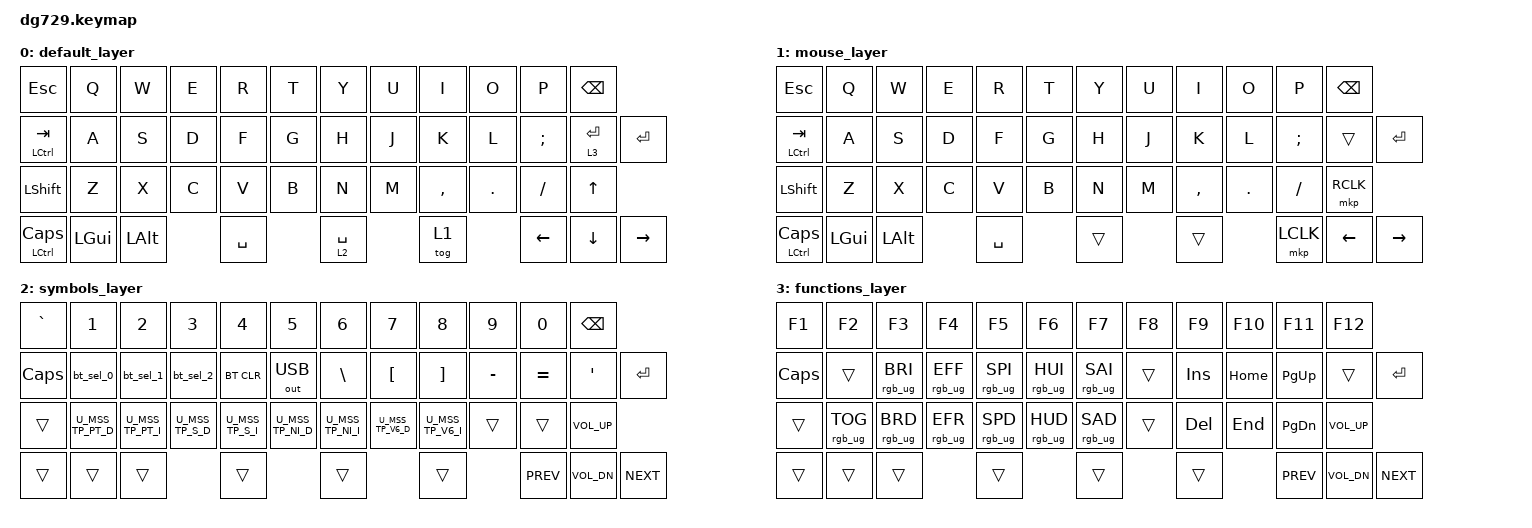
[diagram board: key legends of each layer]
// #define MOUSE_MOVING_LAYER 2

#include <behaviors.dtsi>
#include <behaviors/mouse_keys.dtsi>
#include <dt-bindings/zmk/bt.h>
#include <dt-bindings/zmk/keys.h>
#include <dt-bindings/zmk/mouse.h>
#include <dt-bindings/zmk/outputs.h>
#include <dt-bindings/zmk/rgb.h>
#include "includes/trackpoint.dtsi"

/ {
  macros {
    bt_sel_0: bt_profile_macro_0 {
      compatible = "zmk,behavior-macro";
      #binding-cells = <0>;
      bindings = <&out OUT_BLE>, <&bt BT_SEL 0>;
    };

    bt_sel_1: bt_profile_macro_1 {
      compatible = "zmk,behavior-macro";
      #binding-cells = <0>;
      bindings = <&out OUT_BLE>, <&bt BT_SEL 1>;
    };

    bt_sel_2: bt_profile_macro_2 {
      compatible = "zmk,behavior-macro";
      #binding-cells = <0>;
      bindings = <&out OUT_BLE>, <&bt BT_SEL 2>;
    };
  };

  behaviors {
    volume_control: volume_control_behavior {
      compatible = "zmk,behavior-sensor-rotate";
      #sensor-binding-cells = <0>;
      bindings = <&kp C_VOL_UP>, <&kp C_VOL_DN>;
    };

    mouse_scroll: mouse_scroll_behavior {
      compatible = "zmk,behavior-sensor-rotate";
      #sensor-binding-cells = <0>;
      bindings = <&msc SCRL_UP>, <&msc SCRL_DOWN>;
      tap-ms = <120>;
    };

    screen_brightness: screen_brightness_behavior {
      compatible = "zmk,behavior-sensor-rotate";
      #sensor-binding-cells = <0>;
      bindings = <&kp C_BRI_UP>, <&kp C_BRI_DN>;
    };

    rgb_brightness: rgb_brightness_behavior {
      compatible = "zmk,behavior-sensor-rotate";
      #sensor-binding-cells = <0>;
      bindings = <&rgb_ug RGB_BRI>, <&rgb_ug RGB_BRD>;
    };
  };

  keymap {
    compatible = "zmk,keymap";

    default_layer {
      bindings = <
        &kp ESC           &kp Q     &kp W     &kp E  &kp R      &kp T  &kp Y        &kp U  &kp I      &kp O    &kp P      &kp BACKSPACE
        &mt LCTRL TAB     &kp A     &kp S     &kp D  &kp F      &kp G  &kp H        &kp J  &kp K      &kp L    &kp SEMI   &lt 3 ENTER    &kp ENTER
        &kp LSHIFT        &kp Z     &kp X     &kp C  &kp V      &kp B  &kp N        &kp M  &kp COMMA  &kp DOT  &kp SLASH  &kp UP
        &mt LCTRL CAPS    &kp LGUI  &kp LALT         &kp SPACE         &lt 2 SPACE         &tog 1              &kp LEFT   &kp DOWN       &kp RIGHT
      >;
      sensor-bindings = <&volume_control>;
    };

    mouse_layer {
      bindings = <
        &kp ESC          &kp Q     &kp W     &kp E  &kp R      &kp T  &kp Y   &kp U  &kp I      &kp O    &kp P      &kp BACKSPACE
        &mt LCTRL TAB    &kp A     &kp S     &kp D  &kp F      &kp G  &kp H   &kp J  &kp K      &kp L    &kp SEMI   &trans         &kp ENTER
        &kp LSHIFT       &kp Z     &kp X     &kp C  &kp V      &kp B  &kp N   &kp M  &kp COMMA  &kp DOT  &kp SLASH  &mkp RCLK
        &mt LCTRL CAPS   &kp LGUI  &kp LALT         &kp SPACE         &trans         &trans              &mkp LCLK  &kp LEFT       &kp RIGHT
      >;
      sensor-bindings = <&mouse_scroll>;
    };

    symbols_layer {
      bindings = <
        &kp GRAVE  &kp N1         &kp N2         &kp N3        &kp N4        &kp N5         &kp N6         &kp N7         &kp N8         &kp N9     &kp N0      &kp BACKSPACE
        &kp CAPS   &bt_sel_0      &bt_sel_1      &bt_sel_2     &bt BT_CLR    &out OUT_USB   &kp BACKSLASH  &kp LBKT       &kp RBKT       &kp MINUS  &kp EQUAL   &kp SQT        &kp ENTER
        &trans     U_MSS_TP_PT_D  U_MSS_TP_PT_I  U_MSS_TP_S_D  U_MSS_TP_S_I  U_MSS_TP_NI_D  U_MSS_TP_NI_I  U_MSS_TP_V6_D  U_MSS_TP_V6_I  &trans     &trans      &kp C_VOL_UP
        &trans     &trans         &trans                       &trans                       &trans                        &trans                    &kp C_PREV  &kp C_VOL_DN   &kp C_NEXT
      >;
      sensor-bindings = <&screen_brightness>;
    };

    functions_layer {
      bindings = <
        &kp F1    &kp F2           &kp F3           &kp F4           &kp F5           &kp F6           &kp F7           &kp F8  &kp F9      &kp F10   &kp F11     &kp F12
        &kp CAPS  &trans           &rgb_ug RGB_BRI  &rgb_ug RGB_EFF  &rgb_ug RGB_SPI  &rgb_ug RGB_HUI  &rgb_ug RGB_SAI  &trans  &kp INSERT  &kp HOME  &kp PG_UP   &trans        &kp ENTER
        &trans    &rgb_ug RGB_TOG  &rgb_ug RGB_BRD  &rgb_ug RGB_EFR  &rgb_ug RGB_SPD  &rgb_ug RGB_HUD  &rgb_ug RGB_SAD  &trans  &kp DELETE  &kp END   &kp PG_DN   &kp C_VOL_UP
        &trans    &trans           &trans                            &trans                            &trans                   &trans                &kp C_PREV  &kp C_VOL_DN  &kp C_NEXT
      >;
      sensor-bindings = <&rgb_brightness>;
    };
  };
};
